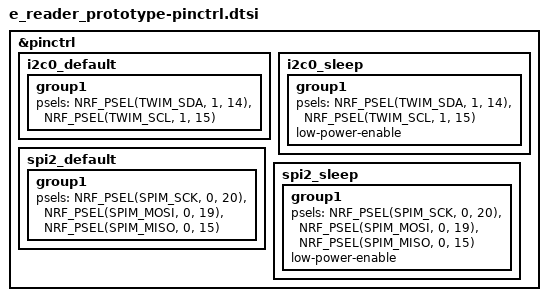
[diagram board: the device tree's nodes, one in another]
&pinctrl {
  i2c0_default: i2c0_default {
    group1 {
      psels = <NRF_PSEL(TWIM_SDA, 1, 14)>,
              <NRF_PSEL(TWIM_SCL, 1, 15)>;
    };
  };

  i2c0_sleep: i2c0_sleep {
    group1 {
      psels = <NRF_PSEL(TWIM_SDA, 1, 14)>,
              <NRF_PSEL(TWIM_SCL, 1, 15)>;
      low-power-enable;
    };
  };

  spi2_default: spi2_default {
    group1 {
      psels = <NRF_PSEL(SPIM_SCK, 0, 20)>,
              <NRF_PSEL(SPIM_MOSI, 0, 19)>,
              <NRF_PSEL(SPIM_MISO, 0, 15)>;
    };
  };

  spi2_sleep: spi2_sleep {
    group1 {
      psels = <NRF_PSEL(SPIM_SCK, 0, 20)>,
              <NRF_PSEL(SPIM_MOSI, 0, 19)>,
              <NRF_PSEL(SPIM_MISO, 0, 15)>;
      low-power-enable;
    };
  };
};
